AUTOSAR XML (schema 4-3-0)
package /e/s1
  client server interface i1
  sender receiver interface i2
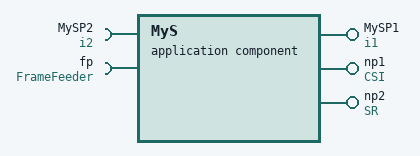
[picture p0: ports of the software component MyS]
  application sw component type MyS
    provide port MySP1: provided-interface=i1
    require port MySP2: required-interface=i2
    provide port np1: provided-interface=CSI
    provide port np2: provided-interface=SR
    require port fp: required-interface=FrameFeeder
package /m1
  application sw component type SwcM1
